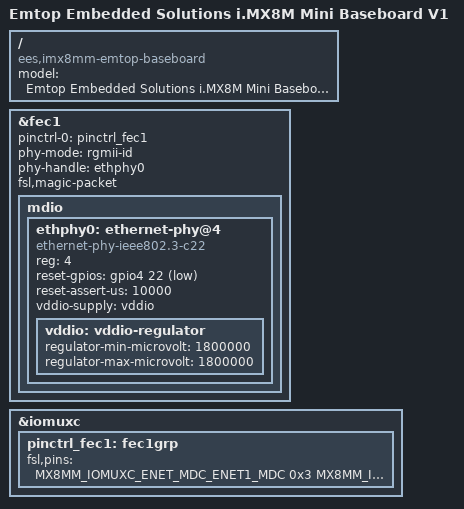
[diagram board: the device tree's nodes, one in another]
// SPDX-License-Identifier: (GPL-2.0+ OR MIT)
/*
 * Copyright 2023 Emtop Embedded Solutions
 */

/dts-v1/;

#include "imx8mm-emtop-som.dtsi"

/ {
	model = "Emtop Embedded Solutions i.MX8M Mini Baseboard V1";
	compatible = "ees,imx8mm-emtop-baseboard", "ees,imx8mm-emtop-som",
		"fsl,imx8mm";
};

&fec1 {
	pinctrl-names = "default";
	pinctrl-0 = <&pinctrl_fec1>;
	phy-mode = "rgmii-id";
	phy-handle = <&ethphy0>;
	fsl,magic-packet;
	status = "okay";

	mdio {
		#address-cells = <1>;
		#size-cells = <0>;

		ethphy0: ethernet-phy@4 {
			compatible = "ethernet-phy-ieee802.3-c22";
			reg = <4>;
			reset-gpios = <&gpio4 22 GPIO_ACTIVE_LOW>;
			reset-assert-us = <10000>;
			vddio-supply = <&vddio>;

			vddio: vddio-regulator {
				regulator-min-microvolt = <1800000>;
				regulator-max-microvolt = <1800000>;
			};
		};
	};
};

&iomuxc {
	pinctrl_fec1: fec1grp {
		fsl,pins = <
			MX8MM_IOMUXC_ENET_MDC_ENET1_MDC                 0x3
			MX8MM_IOMUXC_ENET_MDIO_ENET1_MDIO               0x3
			MX8MM_IOMUXC_ENET_TD3_ENET1_RGMII_TD3           0x1f
			MX8MM_IOMUXC_ENET_TD2_ENET1_RGMII_TD2           0x1f
			MX8MM_IOMUXC_ENET_TD1_ENET1_RGMII_TD1           0x1f
			MX8MM_IOMUXC_ENET_TD0_ENET1_RGMII_TD0           0x1f
			MX8MM_IOMUXC_ENET_RD3_ENET1_RGMII_RD3           0x91
			MX8MM_IOMUXC_ENET_RD2_ENET1_RGMII_RD2           0x91
			MX8MM_IOMUXC_ENET_RD1_ENET1_RGMII_RD1           0x91
			MX8MM_IOMUXC_ENET_RD0_ENET1_RGMII_RD0           0x91
			MX8MM_IOMUXC_ENET_TXC_ENET1_RGMII_TXC           0x1f
			MX8MM_IOMUXC_ENET_RXC_ENET1_RGMII_RXC           0x91
			MX8MM_IOMUXC_ENET_RX_CTL_ENET1_RGMII_RX_CTL     0x91
			MX8MM_IOMUXC_ENET_TX_CTL_ENET1_RGMII_TX_CTL     0x1f
			MX8MM_IOMUXC_SAI2_RXC_GPIO4_IO22                0x19
		>;
	};
};
